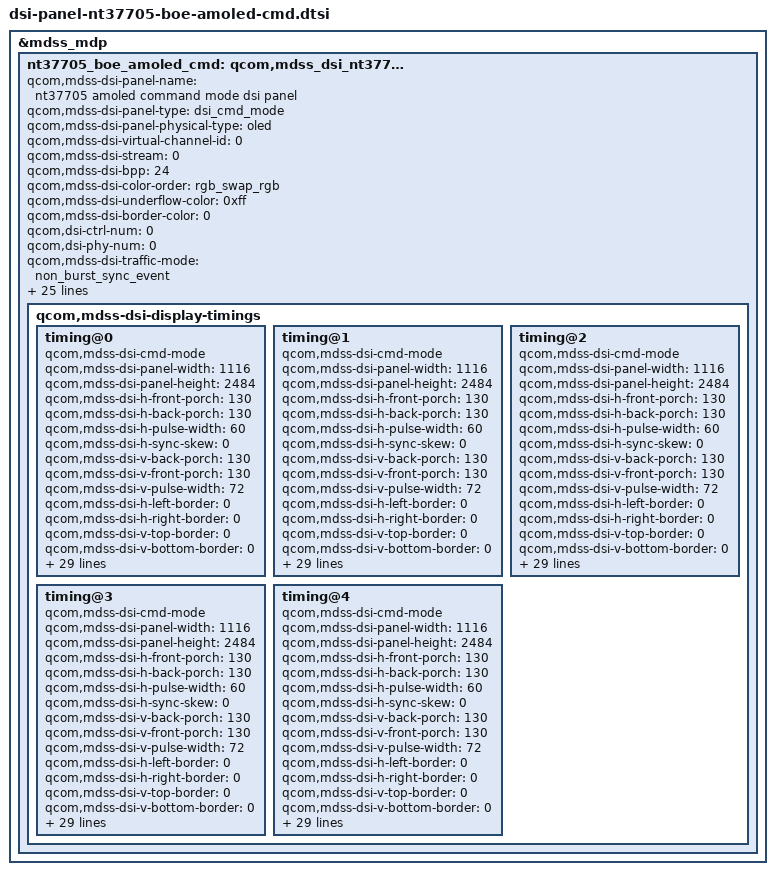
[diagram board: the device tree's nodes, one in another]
&mdss_mdp {
	nt37705_boe_amoled_cmd: qcom,mdss_dsi_nt37705_boe_amoled_cmd {
		qcom,mdss-dsi-panel-name = "nt37705 amoled command mode dsi panel";

		qcom,mdss-dsi-panel-type = "dsi_cmd_mode";
		qcom,mdss-dsi-panel-physical-type = "oled";
		qcom,mdss-dsi-virtual-channel-id = <0>;
		qcom,mdss-dsi-stream = <0>;
		qcom,mdss-dsi-bpp = <24>;
		qcom,mdss-dsi-color-order = "rgb_swap_rgb";
		qcom,mdss-dsi-underflow-color = <0xff>;
		qcom,mdss-dsi-border-color = <0>;
		qcom,dsi-ctrl-num = <0>;
		qcom,dsi-phy-num = <0>;

		qcom,mdss-dsi-traffic-mode = "non_burst_sync_event";
		qcom,mdss-dsi-lane-map = "lane_map_0123";
		qcom,mdss-dsi-bllp-eof-power-mode;
		qcom,mdss-dsi-bllp-power-mode;

		qcom,mdss-dsi-lp11-init;
		qcom,mdss-dsi-lane-0-state;
		qcom,mdss-dsi-lane-1-state;
		qcom,mdss-dsi-lane-2-state;
		qcom,mdss-dsi-lane-3-state;
		qcom,mdss-dsi-dma-trigger = "trigger_sw";
		qcom,mdss-dsi-mdp-trigger = "none";
		qcom,mdss-dsi-reset-sequence = <1 10>, <0 5>, <1 10>;
		/*qcom,mdss-dsi-panel-hdr-color-primaries = <14500 15500 32000
				17000 15500 30000 8000 3000>;
		qcom,mdss-dsi-panel-peak-brightness = <4200000>;
		qcom,mdss-dsi-panel-blackness-level = <3230>;*/
		qcom,mdss-dsi-te-pin-select = <1>;
 		qcom,mdss-dsi-wr-mem-start = <0x2c>;
 		qcom,mdss-dsi-wr-mem-continue = <0x3c>;
 		qcom,mdss-dsi-te-dcs-command = <1>;
 		qcom,mdss-dsi-te-check-enable;
 		qcom,mdss-dsi-te-using-te-pin;
 		qcom,mdss-dsi-t-clk-post = <0x9f>;//0x9f
 		qcom,mdss-dsi-t-clk-pre = <0x0f>;//0x0f
		qcom,mdss-pan-physical-width-dimension = <66>;
		qcom,mdss-pan-physical-height-dimension = <146>;

		qcom,bl-dsc-cmd-state = "dsi_lp_mode";
		qcom,dynamic-mode-switch-enabled;
		qcom,dynamic-mode-switch-type = "dynamic-resolution-switch-immediate";

		qcom,mdss-dsi-display-timings {
			timing@0 {
				qcom,mdss-dsi-cmd-mode;
				qcom,mdss-dsi-panel-width = <1116>;
				qcom,mdss-dsi-panel-height = <2484>;
				qcom,mdss-dsi-h-front-porch = <130>; //100
				qcom,mdss-dsi-h-back-porch = <130>; //100
				qcom,mdss-dsi-h-pulse-width = <60>; //30
				qcom,mdss-dsi-h-sync-skew = <0>;
				qcom,mdss-dsi-v-back-porch = <130>; //70
				qcom,mdss-dsi-v-front-porch = <130>; //70
				qcom,mdss-dsi-v-pulse-width = <72>; //48
				qcom,mdss-dsi-h-left-border = <0>;
				qcom,mdss-dsi-h-right-border = <0>;
				qcom,mdss-dsi-v-top-border = <0>;
				qcom,mdss-dsi-v-bottom-border = <0>;
				qcom,mdss-dsi-panel-jitter = <0x4 0x1>;//
				qcom,mdss-dsi-panel-framerate = <60>;
				qcom,mdss-dsi-on-command = [
					//## Page 0
					// Skip mode setting
					39 01 00 00 00 00 06 F0 55 AA 52 08 00

					// LP_MODE=1
					15 01 00 00 00 00 02 6F 1B
					15 01 00 00 00 00 02 BA 18

					// Skip frame Seq1
					15 01 00 00 00 00 02 6F 1C
					39 01 00 00 00 00 11 BA 01 01 01 01 01 00 00 00 01 00 00 00 00 00 00 00

					// Skip frame Seq2
					15 01 00 00 00 00 02 6F 2C
					39 01 00 00 00 00 11 BA 00 00 00 00 00 00 00 00 00 00 00 00 00 00 00 00

					// Skip frame Seq3
					15 01 00 00 00 00 02 6F 3C
					39 01 00 00 00 00 11 BA 00 00 00 00 00 00 00 00 00 00 00 00 00 00 00 00

					// Skip frame Seq4
					15 01 00 00 00 00 02 6F 4C
					39 01 00 00 00 00 11 BA 00 00 00 00 00 00 00 00 00 00 00 00 00 00 00 00

					// Skip frame Seq5
					15 01 00 00 00 00 02 6F 5C
					39 01 00 00 00 00 11 BA 01 01 01 01 01 01 01 01 01 01 01 01 01 01 01 01

					// Skip frame Seq5 of Blanking frame
					15 01 00 00 00 00 02 6F 6C
					39 01 00 00 00 00 11 BA 01 01 02 03 04 05 01 77 01 01 01 0B 01 1D 01 01

					// Skip frame Seq5 of blanking Frame A
					15 01 00 00 00 00 02 6F 7C
					39 01 00 00 00 00 11 BA 01 01 02 03 04 05 01 77 01 01 01 0B 01 1D 01 01

					// Skip frame Seq5 of blanking Frame B
					15 01 00 00 00 00 02 6F 8C
					39 01 00 00 00 00 11 BA 00 00 00 00 00 00 00 00 00 00 00 00 00 00 00 00

					// Seq cycle setting
					15 01 00 00 00 00 02 6F 9C
					39 01 00 00 00 00 09 BA 11 11 00 00 00 00 00 00

					// Seq1to4_sel_mode
					15 01 00 00 00 00 02 6F A4
					39 01 00 00 00 00 05 BA 00 00 00 00

					// Skip mode FCON SEL
					15 01 00 00 00 00 02 6F A8
					39 01 00 00 00 00 09 BA 22 22 22 22 22 22 22 22

					// Skip mode GMA SEL
					15 01 00 00 00 00 02 6F B0
					39 01 00 00 00 00 09 BA 22 22 22 22 22 22 22 22

					// Page 1
					39 01 00 00 00 00 06 F0 55 AA 52 08 01

					// #Adjust Voltage for DVDD
					15 01 00 00 00 00 02 6F 05
					39 01 00 00 00 00 05 C5 15 15 15 DD

					// Page 0
					39 01 00 00 00 00 06 F0 55 AA 52 08 00

					// #AOD FD ON
					15 01 00 00 00 00 02 6F 0E
					15 01 00 00 00 00 02 B5 32

					//  Page disable
					39 01 00 00 00 00 06 F0 55 AA 52 00 00

					// CMD3_Page0
					39 01 00 00 00 00 05 FF AA 55 A5 80

					// #Idle_SRE_off
					15 01 00 00 00 00 02 6F 19
					15 01 00 00 00 00 02 F2 00

					// #SWC slew ratio
					15 01 00 00 00 00 02 6F 1A
					15 01 00 00 00 00 02 F4 55

					// #OSC2=139.6MHz
					15 01 00 00 00 00 02 6F 11
					39 01 00 00 00 00 03 F8 01 7F

					// #OSC1=139.6MHz
					15 01 00 00 00 00 02 6F 2D
					39 01 00 00 00 00 03 F8 01 20

					// CMD3_Page1
					39 01 00 00 00 00 05 FF AA 55 A5 81

					// #porch ld disable
					15 01 00 00 00 00 02 6F 05
					15 01 00 00 00 00 02 FE 3C

					// #WB_PS_Build_DLY
					15 01 00 00 00 00 02 6F 02
					15 01 00 00 00 00 02 F9 04

					// #OSC divider OPT
					15 01 00 00 00 00 02 6F 1E
					15 01 00 00 00 00 02 FB 0F

					// #BOIS clk On
					15 01 00 00 00 00 02 6F 0F
					15 01 00 00 00 00 02 F5 20

					// #tg_opt(skip_TE
					15 01 00 00 00 00 02 6F 0D
					15 01 00 00 00 00 02 FB 80

					// CMD3_Page3
					39 01 00 00 00 00 05 FF AA 55 A5 83

					// #VRAM
					15 01 00 00 00 00 02 6F 12
					15 01 00 00 00 00 02 FE 41

					// #Demura_xl1205
					15 01 00 00 00 00 02 6F 13
					15 01 00 00 00 00 02 FD 21

					// #CMD Disable
					39 01 00 00 00 00 05 FF AA 55 A5 00

					// #TE ON
					05 01 00 00 00 00 01 35

					// #BC Dimming oFF
					15 01 00 00 00 00 02 53 20
					// #CASET
					39 01 00 00 00 00 05 2A 00 00 04 5B
					// #PASET
					39 01 00 00 00 00 05 2B 00 00 09 B3

					// #Normal GMA
					15 01 00 00 00 00 02 26 00

					// Normal DBV
					39 01 00 00 00 00 03 51 0D BB

					// idle DBV
					15 01 00 00 00 00 02 6F 04
					39 01 00 00 00 00 03 51 0F FE

					// #CMD1, DPC Temperature
					39 01 00 00 00 00 03 81 01 19

					// VESA off,IC en/decode
					//39 01 00 00 00 00 03 90 00 00

					// DSC setting
					15 01 00 00 00 00 02 03 01
					39 01 00 00 00 00 03 90 03 03
					39 01 00 00 00 00 13 91 89 28 00 0C D2 00 02 2F 01 18 00 07 09 75 08 34 10 F0

					// Normal Display
					15 01 00 00 00 00 02 2F 02

					// Setting 60hz
					15 01 00 00 00 00 02 5A 01
					15 01 00 00 00 00 02 2F 30
					15 01 00 00 00 00 02 6D 01

					// Normal Display
					15 01 00 00 78 00 02 11 00

					// Display On
					15 01 00 00 16 00 02 29 00
				];

				qcom,mdss-dsi-dbv-bsd-90hz-12pulse-mode-command = [
					//beside 90hz DBV <= 1290
					//15 01 00 00 00 00 02 2F 02
					39 01 00 00 00 00 06 F0 55 AA 52 08 00
					15 01 00 00 00 00 02 6F 13
					15 01 00 00 00 00 02 B2 4B
				];

				qcom,mdss-dsi-dbv-bsd-90hz-3pulse-mode-command = [
					//beside 90hz DBV > 1290
					//15 01 00 00 00 00 02 2F 02
					39 01 00 00 00 00 06 F0 55 AA 52 08 00
					15 01 00 00 00 00 02 6F 13
					15 01 00 00 00 00 02 B2 42
				];

				qcom,mdss-dsi-off-command = [
					//29 01 00 00 01 00 02 FE 00
					15 01 00 00 01 00 02 28 00
					15 01 00 00 64 00 02 10 00
				];

				qcom,mdss-dsi-timing-switch-command = [
					15 01 00 00 00 00 02 5A 01
					15 01 00 00 00 00 02 2F 30
					15 01 00 00 00 00 02 6D 01
				];

				qcom,mdss-dsi-on-command-state = "dsi_lp_mode";
				//qcom,mdss-dsi-off-command-state = "dsi_hs_mode";
				qcom,mdss-dsi-dbv-bsd-90hz-12pulse-mode-command-state = "dsi_lp_mode";
				qcom,mdss-dsi-dbv-bsd-90hz-3pulse-mode-command-state = "dsi_lp_mode";
				qcom,mdss-dsi-timing-switch-command-state = "dsi_lp_mode";

				qcom,mdss-dsi-h-sync-pulse = <0>;
				qcom,compression-mode = "dsc";
				qcom,mdss-dsc-version = <0x11>;
				qcom,mdss-dsc-scr-version = <0x0>;
				qcom,mdss-dsc-slice-height = <12>;
				qcom,mdss-dsc-slice-width = <558>;
				qcom,mdss-dsc-slice-per-pkt = <2>;
				qcom,mdss-dsc-bit-per-component = <8>;
				qcom,mdss-dsc-bit-per-pixel = <8>;
				qcom,mdss-dsc-block-prediction-enable;
			};

			timing@1 {
				qcom,mdss-dsi-cmd-mode;
				qcom,mdss-dsi-panel-width = <1116>;
				qcom,mdss-dsi-panel-height = <2484>;
				qcom,mdss-dsi-h-front-porch = <130>;
				qcom,mdss-dsi-h-back-porch = <130>;
				qcom,mdss-dsi-h-pulse-width = <60>;
				qcom,mdss-dsi-h-sync-skew = <0>;
				qcom,mdss-dsi-v-back-porch = <130>;
				qcom,mdss-dsi-v-front-porch = <130>;
				qcom,mdss-dsi-v-pulse-width = <72>;
				qcom,mdss-dsi-h-left-border = <0>;
				qcom,mdss-dsi-h-right-border = <0>;
				qcom,mdss-dsi-v-top-border = <0>;
				qcom,mdss-dsi-v-bottom-border = <0>;
				qcom,mdss-dsi-panel-jitter = <0x4 0x1>;//
				qcom,mdss-dsi-panel-framerate = <120>;
				qcom,mdss-dsi-on-command = [
					//## Page 0
					// Skip mode setting
					39 01 00 00 00 00 06 F0 55 AA 52 08 00

					// LP_MODE=1
					15 01 00 00 00 00 02 6F 1B
					15 01 00 00 00 00 02 BA 18

					// Skip frame Seq1
					15 01 00 00 00 00 02 6F 1C
					39 01 00 00 00 00 11 BA 01 01 01 01 01 00 00 00 01 00 00 00 00 00 00 00

					// Skip frame Seq2
					15 01 00 00 00 00 02 6F 2C
					39 01 00 00 00 00 11 BA 00 00 00 00 00 00 00 00 00 00 00 00 00 00 00 00

					// Skip frame Seq3
					15 01 00 00 00 00 02 6F 3C
					39 01 00 00 00 00 11 BA 00 00 00 00 00 00 00 00 00 00 00 00 00 00 00 00

					// Skip frame Seq4
					15 01 00 00 00 00 02 6F 4C
					39 01 00 00 00 00 11 BA 00 00 00 00 00 00 00 00 00 00 00 00 00 00 00 00

					// Skip frame Seq5
					15 01 00 00 00 00 02 6F 5C
					39 01 00 00 00 00 11 BA 01 01 01 01 01 01 01 01 01 01 01 01 01 01 01 01

					// Skip frame Seq5 of Blanking frame
					15 01 00 00 00 00 02 6F 6C
					39 01 00 00 00 00 11 BA 01 01 02 03 04 05 01 77 01 01 01 0B 01 1D 01 01

					// Skip frame Seq5 of blanking Frame A
					15 01 00 00 00 00 02 6F 7C
					39 01 00 00 00 00 11 BA 01 01 02 03 04 05 01 77 01 01 01 0B 01 1D 01 01

					// Skip frame Seq5 of blanking Frame B
					15 01 00 00 00 00 02 6F 8C
					39 01 00 00 00 00 11 BA 00 00 00 00 00 00 00 00 00 00 00 00 00 00 00 00

					// Seq cycle setting
					15 01 00 00 00 00 02 6F 9C
					39 01 00 00 00 00 09 BA 11 11 00 00 00 00 00 00

					// Seq1to4_sel_mode
					15 01 00 00 00 00 02 6F A4
					39 01 00 00 00 00 05 BA 00 00 00 00

					// Skip mode FCON SEL
					15 01 00 00 00 00 02 6F A8
					39 01 00 00 00 00 09 BA 22 22 22 22 22 22 22 22

					// Skip mode GMA SEL
					15 01 00 00 00 00 02 6F B0
					39 01 00 00 00 00 09 BA 22 22 22 22 22 22 22 22

					// Page 1
					39 01 00 00 00 00 06 F0 55 AA 52 08 01

					// #Adjust Voltage for DVDD
					15 01 00 00 00 00 02 6F 05
					39 01 00 00 00 00 05 C5 15 15 15 DD

					// Page 0
					39 01 00 00 00 00 06 F0 55 AA 52 08 00

					// #AOD FD ON
					15 01 00 00 00 00 02 6F 0E
					15 01 00 00 00 00 02 B5 32

					//  Page disable
					39 01 00 00 00 00 06 F0 55 AA 52 00 00

					// CMD3_Page0
					39 01 00 00 00 00 05 FF AA 55 A5 80

					// #Idle_SRE_off
					15 01 00 00 00 00 02 6F 19
					15 01 00 00 00 00 02 F2 00

					// #SWC slew ratio
					15 01 00 00 00 00 02 6F 1A
					15 01 00 00 00 00 02 F4 55

					// #OSC2=139.6MHz
					15 01 00 00 00 00 02 6F 11
					39 01 00 00 00 00 03 F8 01 7F

					// #OSC1=139.6MHz
					15 01 00 00 00 00 02 6F 2D
					39 01 00 00 00 00 03 F8 01 20

					// CMD3_Page1
					39 01 00 00 00 00 05 FF AA 55 A5 81

					// #porch ld disable
					15 01 00 00 00 00 02 6F 05
					15 01 00 00 00 00 02 FE 3C

					// #WB_PS_Build_DLY
					15 01 00 00 00 00 02 6F 02
					15 01 00 00 00 00 02 F9 04

					// #OSC divider OPT
					15 01 00 00 00 00 02 6F 1E
					15 01 00 00 00 00 02 FB 0F

					// #BOIS clk On
					15 01 00 00 00 00 02 6F 0F
					15 01 00 00 00 00 02 F5 20

					// #tg_opt(skip_TE
					15 01 00 00 00 00 02 6F 0D
					15 01 00 00 00 00 02 FB 80

					// CMD3_Page3
					39 01 00 00 00 00 05 FF AA 55 A5 83

					// #VRAM
					15 01 00 00 00 00 02 6F 12
					15 01 00 00 00 00 02 FE 41

					// #Demura_xl1205
					15 01 00 00 00 00 02 6F 13
					15 01 00 00 00 00 02 FD 21

					// #CMD Disable
					39 01 00 00 00 00 05 FF AA 55 A5 00

					// #TE ON
					05 01 00 00 00 00 01 35

					// #BC Dimming oFF
					15 01 00 00 00 00 02 53 20
					// #CASET
					39 01 00 00 00 00 05 2A 00 00 04 5B
					// #PASET
					39 01 00 00 00 00 05 2B 00 00 09 B3

					// #Normal GMA
					15 01 00 00 00 00 02 26 00

					// Normal DBV
					39 01 00 00 00 00 03 51 0D BB

					// idle DBV
					15 01 00 00 00 00 02 6F 04
					39 01 00 00 00 00 03 51 0F FE

					// #CMD1, DPC Temperature
					39 01 00 00 00 00 03 81 01 19

					// VESA off,IC en/decode
					//39 01 00 00 00 00 03 90 00 00

					// DSC setting
					15 01 00 00 00 00 02 03 01
					39 01 00 00 00 00 03 90 03 03
					39 01 00 00 00 00 13 91 89 28 00 0C D2 00 02 2F 01 18 00 07 09 75 08 34 10 F0

					// Normal Display
					//15 01 00 00 00 00 02 2F 02

					// Setting 60hz
					15 01 00 00 00 00 02 5A 01
					15 01 00 00 00 00 02 2F 30
					15 01 00 00 00 00 02 6D 01

					15 01 00 00 00 00 02 2F 02

					// Normal Display
					15 01 00 00 78 00 02 11 00

					// Display On
					15 01 00 00 16 00 02 29 00
				];

				qcom,mdss-dsi-dbv-bsd-90hz-12pulse-mode-command = [
					//beside 90hz and DBV <= 1290
					//15 01 00 00 00 00 02 2F 02
					39 01 00 00 00 00 06 F0 55 AA 52 08 00
					15 01 00 00 00 00 02 6F 13
					15 01 00 00 00 00 02 B2 4B
				];

				qcom,mdss-dsi-dbv-bsd-90hz-3pulse-mode-command = [
					//beside 90hz and DBV > 1290
					//15 01 00 00 00 00 02 2F 02
					39 01 00 00 00 00 06 F0 55 AA 52 08 00
					15 01 00 00 00 00 02 6F 13
					15 01 00 00 00 00 02 B2 42
				];

				qcom,mdss-dsi-off-command = [
					//29 01 00 00 01 00 02 FE 00
					15 01 00 00 01 00 02 28 00
					15 01 00 00 64 00 02 10 00
				];

				qcom,mdss-dsi-timing-switch-command = [
					15 01 00 00 00 00 02 2F 02
				];

				qcom,mdss-dsi-on-command-state = "dsi_lp_mode";
				//qcom,mdss-dsi-off-command-state = "dsi_hs_mode";
				qcom,mdss-dsi-dbv-bsd-90hz-12pulse-mode-command-state = "dsi_lp_mode";
				qcom,mdss-dsi-dbv-bsd-90hz-3pulse-mode-command-state = "dsi_lp_mode";
				qcom,mdss-dsi-timing-switch-command-state = "dsi_lp_mode";

				qcom,mdss-dsi-h-sync-pulse = <0>;
				qcom,compression-mode = "dsc";
				qcom,mdss-dsc-version = <0x11>;
				qcom,mdss-dsc-scr-version = <0x0>;
				qcom,mdss-dsc-slice-height = <12>;
				qcom,mdss-dsc-slice-width = <558>;
				qcom,mdss-dsc-slice-per-pkt = <2>;
				qcom,mdss-dsc-bit-per-component = <8>;
				qcom,mdss-dsc-bit-per-pixel = <8>;
				qcom,mdss-dsc-block-prediction-enable;
			};

			timing@2 {
				qcom,mdss-dsi-cmd-mode;
				qcom,mdss-dsi-panel-width = <1116>;
				qcom,mdss-dsi-panel-height = <2484>;
				qcom,mdss-dsi-h-front-porch = <130>;
				qcom,mdss-dsi-h-back-porch = <130>;
				qcom,mdss-dsi-h-pulse-width = <60>;
				qcom,mdss-dsi-h-sync-skew = <0>;
				qcom,mdss-dsi-v-back-porch = <130>;
				qcom,mdss-dsi-v-front-porch = <130>;
				qcom,mdss-dsi-v-pulse-width = <72>;
				qcom,mdss-dsi-h-left-border = <0>;
				qcom,mdss-dsi-h-right-border = <0>;
				qcom,mdss-dsi-v-top-border = <0>;
				qcom,mdss-dsi-v-bottom-border = <0>;
				qcom,mdss-dsi-panel-jitter = <0x4 0x1>;//
				qcom,mdss-dsi-panel-framerate = <90>;
				qcom,mdss-dsi-on-command = [
					//## Page 0
					// Skip mode setting
					39 01 00 00 00 00 06 F0 55 AA 52 08 00

					// LP_MODE=1
					15 01 00 00 00 00 02 6F 1B
					15 01 00 00 00 00 02 BA 18

					// Skip frame Seq1
					15 01 00 00 00 00 02 6F 1C
					39 01 00 00 00 00 11 BA 01 01 01 01 01 00 00 00 01 00 00 00 00 00 00 00

					// Skip frame Seq2
					15 01 00 00 00 00 02 6F 2C
					39 01 00 00 00 00 11 BA 00 00 00 00 00 00 00 00 00 00 00 00 00 00 00 00

					// Skip frame Seq3
					15 01 00 00 00 00 02 6F 3C
					39 01 00 00 00 00 11 BA 00 00 00 00 00 00 00 00 00 00 00 00 00 00 00 00

					// Skip frame Seq4
					15 01 00 00 00 00 02 6F 4C
					39 01 00 00 00 00 11 BA 00 00 00 00 00 00 00 00 00 00 00 00 00 00 00 00

					// Skip frame Seq5
					15 01 00 00 00 00 02 6F 5C
					39 01 00 00 00 00 11 BA 01 01 01 01 01 01 01 01 01 01 01 01 01 01 01 01

					// Skip frame Seq5 of Blanking frame
					15 01 00 00 00 00 02 6F 6C
					39 01 00 00 00 00 11 BA 01 01 02 03 04 05 01 77 01 01 01 0B 01 1D 01 01

					// Skip frame Seq5 of blanking Frame A
					15 01 00 00 00 00 02 6F 7C
					39 01 00 00 00 00 11 BA 01 01 02 03 04 05 01 77 01 01 01 0B 01 1D 01 01

					// Skip frame Seq5 of blanking Frame B
					15 01 00 00 00 00 02 6F 8C
					39 01 00 00 00 00 11 BA 00 00 00 00 00 00 00 00 00 00 00 00 00 00 00 00

					// Seq cycle setting
					15 01 00 00 00 00 02 6F 9C
					39 01 00 00 00 00 09 BA 11 11 00 00 00 00 00 00

					// Seq1to4_sel_mode
					15 01 00 00 00 00 02 6F A4
					39 01 00 00 00 00 05 BA 00 00 00 00

					// Skip mode FCON SEL
					15 01 00 00 00 00 02 6F A8
					39 01 00 00 00 00 09 BA 22 22 22 22 22 22 22 22

					// Skip mode GMA SEL
					15 01 00 00 00 00 02 6F B0
					39 01 00 00 00 00 09 BA 22 22 22 22 22 22 22 22

					// Page 1
					39 01 00 00 00 00 06 F0 55 AA 52 08 01

					// #Adjust Voltage for DVDD
					15 01 00 00 00 00 02 6F 05
					39 01 00 00 00 00 05 C5 15 15 15 DD

					// Page 0
					39 01 00 00 00 00 06 F0 55 AA 52 08 00

					// #AOD FD ON
					15 01 00 00 00 00 02 6F 0E
					15 01 00 00 00 00 02 B5 32

					//  Page disable
					39 01 00 00 00 00 06 F0 55 AA 52 00 00

					// CMD3_Page0
					39 01 00 00 00 00 05 FF AA 55 A5 80

					// #Idle_SRE_off
					15 01 00 00 00 00 02 6F 19
					15 01 00 00 00 00 02 F2 00

					// #SWC slew ratio
					15 01 00 00 00 00 02 6F 1A
					15 01 00 00 00 00 02 F4 55

					// #OSC2=139.6MHz
					15 01 00 00 00 00 02 6F 11
					39 01 00 00 00 00 03 F8 01 7F

					// #OSC1=139.6MHz
					15 01 00 00 00 00 02 6F 2D
					39 01 00 00 00 00 03 F8 01 20

					// CMD3_Page1
					39 01 00 00 00 00 05 FF AA 55 A5 81

					// #porch ld disable
					15 01 00 00 00 00 02 6F 05
					15 01 00 00 00 00 02 FE 3C

					// #WB_PS_Build_DLY
					15 01 00 00 00 00 02 6F 02
					15 01 00 00 00 00 02 F9 04

					// #OSC divider OPT
					15 01 00 00 00 00 02 6F 1E
					15 01 00 00 00 00 02 FB 0F

					// #BOIS clk On
					15 01 00 00 00 00 02 6F 0F
					15 01 00 00 00 00 02 F5 20

					// #tg_opt(skip_TE
					15 01 00 00 00 00 02 6F 0D
					15 01 00 00 00 00 02 FB 80

					// CMD3_Page3
					39 01 00 00 00 00 05 FF AA 55 A5 83

					// #VRAM
					15 01 00 00 00 00 02 6F 12
					15 01 00 00 00 00 02 FE 41

					// #Demura_xl1205
					15 01 00 00 00 00 02 6F 13
					15 01 00 00 00 00 02 FD 21

					// #CMD Disable
					39 01 00 00 00 00 05 FF AA 55 A5 00

					// #TE ON
					05 01 00 00 00 00 01 35

					// #BC Dimming oFF
					15 01 00 00 00 00 02 53 20
					// #CASET
					39 01 00 00 00 00 05 2A 00 00 04 5B
					// #PASET
					39 01 00 00 00 00 05 2B 00 00 09 B3

					// #Normal GMA
					15 01 00 00 00 00 02 26 00

					// Normal DBV
					39 01 00 00 00 00 03 51 0D BB

					// idle DBV
					15 01 00 00 00 00 02 6F 04
					39 01 00 00 00 00 03 51 0F FE

					// #CMD1, DPC Temperature
					39 01 00 00 00 00 03 81 01 19

					// VESA off,IC en/decode
					//39 01 00 00 00 00 03 90 00 00

					// DSC setting
					15 01 00 00 00 00 02 03 01
					39 01 00 00 00 00 03 90 03 03
					39 01 00 00 00 00 13 91 89 28 00 0C D2 00 02 2F 01 18 00 07 09 75 08 34 10 F0

					// Normal Display
					//15 01 00 00 00 00 02 2F 02

					// Setting 60hz
					//15 01 00 00 00 00 02 5A 01
					//15 01 00 00 00 00 02 2F 30
					//15 01 00 00 00 00 02 6D 01

					15 01 00 00 00 00 02 2F 01
					//39 01 00 00 00 00 05 F0 55 52 08 00
					//15 01 00 00 00 00 02 6F 12
					//15 01 00 00 00 00 02 B2 03

					// Normal Display
					15 01 00 00 78 00 02 11 00

					// Display On
					15 01 00 00 16 00 02 29 00
				];

				qcom,mdss-dsi-dbv-90hz-16pulse-mode-command = [
					//90hz DBV <= 1290
					//15 01 00 00 00 00 02 2F 01
					39 01 00 00 00 00 06 F0 55 AA 52 08 00
					15 01 00 00 00 00 02 6F 12
					15 01 00 00 00 00 02 B2 0F
				];

				qcom,mdss-dsi-dbv-90hz-4pulse-mode-command = [
					//90hz DBV > 1290
					15 01 00 00 00 00 02 2F 01
					39 01 00 00 00 00 06 F0 55 AA 52 08 00
					15 01 00 00 00 00 02 6F 12
					15 01 00 00 00 00 02 B2 03
				];

				qcom,mdss-dsi-off-command = [
					//29 01 00 00 01 00 02 FE 00
					15 01 00 00 01 00 02 28 00
					15 01 00 00 64 00 02 10 00
				];

				qcom,mdss-dsi-timing-switch-command = [
					15 01 00 00 00 00 02 2F 01
				];

				qcom,mdss-dsi-on-command-state = "dsi_lp_mode";
				//qcom,mdss-dsi-off-command-state = "dsi_hs_mode";
				qcom,mdss-dsi-dbv-90hz-16pulse-mode-command-state = "dsi_lp_mode";
				qcom,mdss-dsi-dbv-90hz-4pulse-mode-command-state = "dsi_lp_mode";
				qcom,mdss-dsi-timing-switch-command-state = "dsi_lp_mode";

				qcom,mdss-dsi-h-sync-pulse = <0>;
				qcom,compression-mode = "dsc";
				qcom,mdss-dsc-version = <0x11>;
				qcom,mdss-dsc-scr-version = <0x0>;
				qcom,mdss-dsc-slice-height = <12>;
				qcom,mdss-dsc-slice-width = <558>;
				qcom,mdss-dsc-slice-per-pkt = <2>;
				qcom,mdss-dsc-bit-per-component = <8>;
				qcom,mdss-dsc-bit-per-pixel = <8>;
				qcom,mdss-dsc-block-prediction-enable;
			};

			timing@3 {
				qcom,mdss-dsi-cmd-mode;
				qcom,mdss-dsi-panel-width = <1116>;
				qcom,mdss-dsi-panel-height = <2484>;
				qcom,mdss-dsi-h-front-porch = <130>;
				qcom,mdss-dsi-h-back-porch = <130>;
				qcom,mdss-dsi-h-pulse-width = <60>;
				qcom,mdss-dsi-h-sync-skew = <0>;
				qcom,mdss-dsi-v-back-porch = <130>;
				qcom,mdss-dsi-v-front-porch = <130>;
				qcom,mdss-dsi-v-pulse-width = <72>;
				qcom,mdss-dsi-h-left-border = <0>;
				qcom,mdss-dsi-h-right-border = <0>;
				qcom,mdss-dsi-v-top-border = <0>;
				qcom,mdss-dsi-v-bottom-border = <0>;
				qcom,mdss-dsi-panel-jitter = <0x4 0x1>;//
				qcom,mdss-dsi-panel-framerate = <30>;
				qcom,mdss-dsi-on-command = [
					//## Page 0
					// Skip mode setting
					39 01 00 00 00 00 06 F0 55 AA 52 08 00

					// LP_MODE=1
					15 01 00 00 00 00 02 6F 1B
					15 01 00 00 00 00 02 BA 18

					// Skip frame Seq1
					15 01 00 00 00 00 02 6F 1C
					39 01 00 00 00 00 11 BA 01 01 01 01 01 00 00 00 01 00 00 00 00 00 00 00

					// Skip frame Seq2
					15 01 00 00 00 00 02 6F 2C
					39 01 00 00 00 00 11 BA 00 00 00 00 00 00 00 00 00 00 00 00 00 00 00 00

					// Skip frame Seq3
					15 01 00 00 00 00 02 6F 3C
					39 01 00 00 00 00 11 BA 00 00 00 00 00 00 00 00 00 00 00 00 00 00 00 00

					// Skip frame Seq4
					15 01 00 00 00 00 02 6F 4C
					39 01 00 00 00 00 11 BA 00 00 00 00 00 00 00 00 00 00 00 00 00 00 00 00

					// Skip frame Seq5
					15 01 00 00 00 00 02 6F 5C
					39 01 00 00 00 00 11 BA 01 01 01 01 01 01 01 01 01 01 01 01 01 01 01 01

					// Skip frame Seq5 of Blanking frame
					15 01 00 00 00 00 02 6F 6C
					39 01 00 00 00 00 11 BA 01 01 02 03 04 05 01 77 01 01 01 0B 01 1D 01 01

					// Skip frame Seq5 of blanking Frame A
					15 01 00 00 00 00 02 6F 7C
					39 01 00 00 00 00 11 BA 01 01 02 03 04 05 01 77 01 01 01 0B 01 1D 01 01

					// Skip frame Seq5 of blanking Frame B
					15 01 00 00 00 00 02 6F 8C
					39 01 00 00 00 00 11 BA 00 00 00 00 00 00 00 00 00 00 00 00 00 00 00 00

					// Seq cycle setting
					15 01 00 00 00 00 02 6F 9C
					39 01 00 00 00 00 09 BA 11 11 00 00 00 00 00 00

					// Seq1to4_sel_mode
					15 01 00 00 00 00 02 6F A4
					39 01 00 00 00 00 05 BA 00 00 00 00

					// Skip mode FCON SEL
					15 01 00 00 00 00 02 6F A8
					39 01 00 00 00 00 09 BA 22 22 22 22 22 22 22 22

					// Skip mode GMA SEL
					15 01 00 00 00 00 02 6F B0
					39 01 00 00 00 00 09 BA 22 22 22 22 22 22 22 22

					// Page 1
					39 01 00 00 00 00 06 F0 55 AA 52 08 01

					// #Adjust Voltage for DVDD
					15 01 00 00 00 00 02 6F 05
					39 01 00 00 00 00 05 C5 15 15 15 DD

					// Page 0
					39 01 00 00 00 00 06 F0 55 AA 52 08 00

					// #AOD FD ON
					15 01 00 00 00 00 02 6F 0E
					15 01 00 00 00 00 02 B5 32

					//  Page disable
					39 01 00 00 00 00 06 F0 55 AA 52 00 00

					// CMD3_Page0
					39 01 00 00 00 00 05 FF AA 55 A5 80

					// #Idle_SRE_off
					15 01 00 00 00 00 02 6F 19
					15 01 00 00 00 00 02 F2 00

					// #SWC slew ratio
					15 01 00 00 00 00 02 6F 1A
					15 01 00 00 00 00 02 F4 55

					// #OSC2=139.6MHz
					15 01 00 00 00 00 02 6F 11
					39 01 00 00 00 00 03 F8 01 7F

					// #OSC1=139.6MHz
					15 01 00 00 00 00 02 6F 2D
					39 01 00 00 00 00 03 F8 01 20

					// CMD3_Page1
					39 01 00 00 00 00 05 FF AA 55 A5 81

					// #porch ld disable
					15 01 00 00 00 00 02 6F 05
					15 01 00 00 00 00 02 FE 3C

					// #WB_PS_Build_DLY
					15 01 00 00 00 00 02 6F 02
					15 01 00 00 00 00 02 F9 04

					// #OSC divider OPT
					15 01 00 00 00 00 02 6F 1E
					15 01 00 00 00 00 02 FB 0F

					// #BOIS clk On
					15 01 00 00 00 00 02 6F 0F
					15 01 00 00 00 00 02 F5 20

					// #tg_opt(skip_TE
					15 01 00 00 00 00 02 6F 0D
					15 01 00 00 00 00 02 FB 80

					// CMD3_Page3
					39 01 00 00 00 00 05 FF AA 55 A5 83

					// #VRAM
					15 01 00 00 00 00 02 6F 12
					15 01 00 00 00 00 02 FE 41

					// #Demura_xl1205
					15 01 00 00 00 00 02 6F 13
					15 01 00 00 00 00 02 FD 21

					// #CMD Disable
					39 01 00 00 00 00 05 FF AA 55 A5 00

					// #TE ON
					05 01 00 00 00 00 01 35

					// #BC Dimming oFF
					15 01 00 00 00 00 02 53 20
					// #CASET
					39 01 00 00 00 00 05 2A 00 00 04 5B
					// #PASET
					39 01 00 00 00 00 05 2B 00 00 09 B3

					// #Normal GMA
					15 01 00 00 00 00 02 26 00

					// Normal DBV
					39 01 00 00 00 00 03 51 0D BB

					// idle DBV
					15 01 00 00 00 00 02 6F 04
					39 01 00 00 00 00 03 51 0F FE

					// #CMD1, DPC Temperature
					39 01 00 00 00 00 03 81 01 19

					// VESA off,IC en/decode
					//39 01 00 00 00 00 03 90 00 00

					// DSC setting
					15 01 00 00 00 00 02 03 01
					39 01 00 00 00 00 03 90 03 03
					39 01 00 00 00 00 13 91 89 28 00 0C D2 00 02 2F 01 18 00 07 09 75 08 34 10 F0

					// Normal Display
					15 01 00 00 00 00 02 2F 02

					// Setting 30hz
					15 01 00 00 00 00 02 5A 01
					15 01 00 00 00 00 02 2F 30
					15 01 00 00 00 00 02 6D 03

					// Normal Display
					15 01 00 00 78 00 02 11 00

					// Display On
					15 01 00 00 16 00 02 29 00
				];

				qcom,mdss-dsi-dbv-bsd-90hz-12pulse-mode-command = [
					//beside 90hz DBV <= 1290
					//15 01 00 00 00 00 02 2F 02
					39 01 00 00 00 00 06 F0 55 AA 52 08 00
					15 01 00 00 00 00 02 6F 13
					15 01 00 00 00 00 02 B2 4B
				];

				qcom,mdss-dsi-dbv-bsd-90hz-3pulse-mode-command = [
					//beside 90hz DBV > 1290
					//15 01 00 00 00 00 02 2F 02
					39 01 00 00 00 00 06 F0 55 AA 52 08 00
					15 01 00 00 00 00 02 6F 13
					15 01 00 00 00 00 02 B2 42
				];

				qcom,mdss-dsi-off-command = [
					//29 01 00 00 01 00 02 FE 00
					15 01 00 00 01 00 02 28 00
					15 01 00 00 64 00 02 10 00
				];

				qcom,mdss-dsi-timing-switch-command = [
					15 01 00 00 00 00 02 5A 01
					15 01 00 00 00 00 02 2F 30
					15 01 00 00 00 00 02 6D 03
				];

				qcom,mdss-dsi-on-command-state = "dsi_lp_mode";
				//qcom,mdss-dsi-off-command-state = "dsi_hs_mode";
				qcom,mdss-dsi-dbv-bsd-90hz-12pulse-mode-command-state = "dsi_lp_mode";
				qcom,mdss-dsi-dbv-bsd-90hz-3pulse-mode-command-state = "dsi_lp_mode";
				qcom,mdss-dsi-timing-switch-command-state = "dsi_lp_mode";

				qcom,mdss-dsi-h-sync-pulse = <0>;
				qcom,compression-mode = "dsc";
				qcom,mdss-dsc-version = <0x11>;
				qcom,mdss-dsc-scr-version = <0x0>;
				qcom,mdss-dsc-slice-height = <12>;
				qcom,mdss-dsc-slice-width = <558>;
				qcom,mdss-dsc-slice-per-pkt = <2>;
				qcom,mdss-dsc-bit-per-component = <8>;
				qcom,mdss-dsc-bit-per-pixel = <8>;
				qcom,mdss-dsc-block-prediction-enable;
			};

			timing@4 {
				qcom,mdss-dsi-cmd-mode;
				qcom,mdss-dsi-panel-width = <1116>;
				qcom,mdss-dsi-panel-height = <2484>;
				qcom,mdss-dsi-h-front-porch = <130>;
				qcom,mdss-dsi-h-back-porch = <130>;
				qcom,mdss-dsi-h-pulse-width = <60>;
				qcom,mdss-dsi-h-sync-skew = <0>;
				qcom,mdss-dsi-v-back-porch = <130>;
				qcom,mdss-dsi-v-front-porch = <130>;
				qcom,mdss-dsi-v-pulse-width = <72>;
				qcom,mdss-dsi-h-left-border = <0>;
				qcom,mdss-dsi-h-right-border = <0>;
				qcom,mdss-dsi-v-top-border = <0>;
				qcom,mdss-dsi-v-bottom-border = <0>;
				qcom,mdss-dsi-panel-jitter = <0x4 0x1>;//
				qcom,mdss-dsi-panel-framerate = <1>;
				qcom,mdss-dsi-on-command = [
					//## Page 0
					// Skip mode setting
					39 01 00 00 00 00 06 F0 55 AA 52 08 00

					// LP_MODE=1
					15 01 00 00 00 00 02 6F 1B
					15 01 00 00 00 00 02 BA 18

					// Skip frame Seq1
					15 01 00 00 00 00 02 6F 1C
					39 01 00 00 00 00 11 BA 01 01 01 01 01 00 00 00 01 00 00 00 00 00 00 00

					// Skip frame Seq2
					15 01 00 00 00 00 02 6F 2C
					39 01 00 00 00 00 11 BA 00 00 00 00 00 00 00 00 00 00 00 00 00 00 00 00

					// Skip frame Seq3
					15 01 00 00 00 00 02 6F 3C
					39 01 00 00 00 00 11 BA 00 00 00 00 00 00 00 00 00 00 00 00 00 00 00 00

					// Skip frame Seq4
					15 01 00 00 00 00 02 6F 4C
					39 01 00 00 00 00 11 BA 00 00 00 00 00 00 00 00 00 00 00 00 00 00 00 00

					// Skip frame Seq5
					15 01 00 00 00 00 02 6F 5C
					39 01 00 00 00 00 11 BA 01 01 01 01 01 01 01 01 01 01 01 01 01 01 01 01

					// Skip frame Seq5 of Blanking frame
					15 01 00 00 00 00 02 6F 6C
					39 01 00 00 00 00 11 BA 01 01 02 03 04 05 01 77 01 01 01 0B 01 1D 01 01

					// Skip frame Seq5 of blanking Frame A
					15 01 00 00 00 00 02 6F 7C
					39 01 00 00 00 00 11 BA 01 01 02 03 04 05 01 77 01 01 01 0B 01 1D 01 01

					// Skip frame Seq5 of blanking Frame B
					15 01 00 00 00 00 02 6F 8C
					39 01 00 00 00 00 11 BA 00 00 00 00 00 00 00 00 00 00 00 00 00 00 00 00

					// Seq cycle setting
					15 01 00 00 00 00 02 6F 9C
					39 01 00 00 00 00 09 BA 11 11 00 00 00 00 00 00

					// Seq1to4_sel_mode
					15 01 00 00 00 00 02 6F A4
					39 01 00 00 00 00 05 BA 00 00 00 00

					// Skip mode FCON SEL
					15 01 00 00 00 00 02 6F A8
					39 01 00 00 00 00 09 BA 22 22 22 22 22 22 22 22

					// Skip mode GMA SEL
					15 01 00 00 00 00 02 6F B0
					39 01 00 00 00 00 09 BA 22 22 22 22 22 22 22 22

					// Page 1
					39 01 00 00 00 00 06 F0 55 AA 52 08 01

					// #Adjust Voltage for DVDD
					15 01 00 00 00 00 02 6F 05
					39 01 00 00 00 00 05 C5 15 15 15 DD

					// Page 0
					39 01 00 00 00 00 06 F0 55 AA 52 08 00

					// #AOD FD ON
					15 01 00 00 00 00 02 6F 0E
					15 01 00 00 00 00 02 B5 32

					//  Page disable
					39 01 00 00 00 00 06 F0 55 AA 52 00 00

					// CMD3_Page0
					39 01 00 00 00 00 05 FF AA 55 A5 80

					// #Idle_SRE_off
					15 01 00 00 00 00 02 6F 19
					15 01 00 00 00 00 02 F2 00

					// #SWC slew ratio
					15 01 00 00 00 00 02 6F 1A
					15 01 00 00 00 00 02 F4 55

					// #OSC2=139.6MHz
					15 01 00 00 00 00 02 6F 11
					39 01 00 00 00 00 03 F8 01 7F

					// #OSC1=139.6MHz
					15 01 00 00 00 00 02 6F 2D
					39 01 00 00 00 00 03 F8 01 20

					// CMD3_Page1
					39 01 00 00 00 00 05 FF AA 55 A5 81

					// #porch ld disable
					15 01 00 00 00 00 02 6F 05
					15 01 00 00 00 00 02 FE 3C

					// #WB_PS_Build_DLY
					15 01 00 00 00 00 02 6F 02
					15 01 00 00 00 00 02 F9 04

					// #OSC divider OPT
					15 01 00 00 00 00 02 6F 1E
					15 01 00 00 00 00 02 FB 0F

					// #BOIS clk On
					15 01 00 00 00 00 02 6F 0F
					15 01 00 00 00 00 02 F5 20

					// #tg_opt(skip_TE
					15 01 00 00 00 00 02 6F 0D
					15 01 00 00 00 00 02 FB 80

					// CMD3_Page3
					39 01 00 00 00 00 05 FF AA 55 A5 83

					// #VRAM
					15 01 00 00 00 00 02 6F 12
					15 01 00 00 00 00 02 FE 41

					// #Demura_xl1205
					15 01 00 00 00 00 02 6F 13
					15 01 00 00 00 00 02 FD 21

					// #CMD Disable
					39 01 00 00 00 00 05 FF AA 55 A5 00

					// #TE ON
					05 01 00 00 00 00 01 35

					// #BC Dimming oFF
					15 01 00 00 00 00 02 53 20
					// #CASET
					39 01 00 00 00 00 05 2A 00 00 04 5B
					// #PASET
					39 01 00 00 00 00 05 2B 00 00 09 B3

					// #Normal GMA
					15 01 00 00 00 00 02 26 00

					// Normal DBV
					39 01 00 00 00 00 03 51 0D BB

					// idle DBV
					15 01 00 00 00 00 02 6F 04
					39 01 00 00 00 00 03 51 0F FE

					// #CMD1, DPC Temperature
					39 01 00 00 00 00 03 81 01 19

					// VESA off,IC en/decode
					//39 01 00 00 00 00 03 90 00 00

					// DSC setting
					15 01 00 00 00 00 02 03 01
					39 01 00 00 00 00 03 90 03 03
					39 01 00 00 00 00 13 91 89 28 00 0C D2 00 02 2F 01 18 00 07 09 75 08 34 10 F0

					// Normal Display
					15 01 00 00 00 00 02 2F 02

					// Setting 1hz
					15 01 00 00 00 00 02 5A 01
					15 01 00 00 00 00 02 2F 30
					15 01 00 00 00 00 02 6D 77

					// Normal Display
					15 01 00 00 78 00 02 11 00

					// Display On
					15 01 00 00 16 00 02 29 00
				];

				qcom,mdss-dsi-dbv-bsd-90hz-12pulse-mode-command = [
					//beside 90hz DBV <= 1290
					//15 01 00 00 00 00 02 2F 02
					39 01 00 00 00 00 06 F0 55 AA 52 08 00
					15 01 00 00 00 00 02 6F 13
					15 01 00 00 00 00 02 B2 4B
				];

				qcom,mdss-dsi-dbv-bsd-90hz-3pulse-mode-command = [
					//beside 90hz DBV > 1290
					//15 01 00 00 00 00 02 2F 02
					39 01 00 00 00 00 06 F0 55 AA 52 08 00
					15 01 00 00 00 00 02 6F 13
					15 01 00 00 00 00 02 B2 42
				];

				qcom,mdss-dsi-off-command = [
					//29 01 00 00 01 00 02 FE 00
					15 01 00 00 01 00 02 28 00
					15 01 00 00 64 00 02 10 00
				];

				qcom,mdss-dsi-timing-switch-command = [
					15 01 00 00 00 00 02 5A 01
					15 01 00 00 00 00 02 2F 30
					15 01 00 00 00 00 02 6D 77
				];

				qcom,mdss-dsi-on-command-state = "dsi_lp_mode";
				//qcom,mdss-dsi-off-command-state = "dsi_hs_mode";
				qcom,mdss-dsi-dbv-bsd-90hz-12pulse-mode-command-state = "dsi_lp_mode";
				qcom,mdss-dsi-dbv-bsd-90hz-3pulse-mode-command-state = "dsi_lp_mode";
				qcom,mdss-dsi-timing-switch-command-state = "dsi_lp_mode";

				qcom,mdss-dsi-h-sync-pulse = <0>;
				qcom,compression-mode = "dsc";
				qcom,mdss-dsc-version = <0x11>;
				qcom,mdss-dsc-scr-version = <0x0>;
				qcom,mdss-dsc-slice-height = <12>;
				qcom,mdss-dsc-slice-width = <558>;
				qcom,mdss-dsc-slice-per-pkt = <2>;
				qcom,mdss-dsc-bit-per-component = <8>;
				qcom,mdss-dsc-bit-per-pixel = <8>;
				qcom,mdss-dsc-block-prediction-enable;
			};
		};
	};
};


